# DEMO register map
Demo chip & friends
Registers are 32-bit, read-write, reset 0x0 unless marked. A register's access mark holds for its fields unless they carry their own. Offsets are from the block's base; lines under a group give offsets from that group; [hi:lo] are bit positions; {n}, {i} and the like mark numbered series; 'fields as' and 'values as' point back to an identical list; <NAME> marks a mode.

## Memory map
0x40001000 UART0
0x40002000 UART1
0x50000000 WIDE

## UART0
Base 0x40001000
Same registers: UART1 0x40002000
0x00 CTRL reset 0x301 — Control register
  [40] OUTSIDE
  [19:16] STATUS ro
  [9:8] MODE
    0=Off; 0b1x=Auto; other=Other
  [8] CLASH
  [0] EN — Enable
{0x10+4i} DATA{i} (i=0..1) 16-bit ro reset 0xFFFF (reset mask 0xFF)
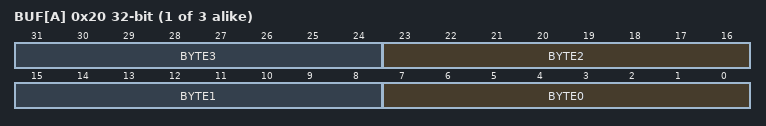
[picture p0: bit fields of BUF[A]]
0x20 BUF[{x}] (x=A,B,C; step 0x4)
  [8n+7:8n] BYTE{n} (n=0..3)
0x40 CTRL2 reset 0x301 — Control register
  fields as CTRL
{0x100+0x10*i} CH{i} (i=0..1) group
  0x04 CFG
    [1:0] SPEED
      0=Off; 0b1x=Auto; other=Other

## WIDE
Base 0x50000000
0x00 HUGE 1024-bit (reset mask 0xFFFFFFFF)
